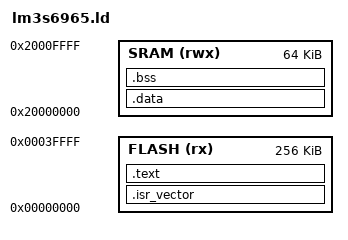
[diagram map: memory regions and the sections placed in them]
MEMORY
{
    FLASH (rx)  : ORIGIN = 0x00000000, LENGTH = 256K
    SRAM  (rwx) : ORIGIN = 0x20000000, LENGTH = 64K
}

ENTRY(Reset_Handler)

SECTIONS
{
    .isr_vector :
    {
        KEEP(*(.isr_vector))
    } > FLASH

    .text :
    {
        *(.text*)
        *(.rodata*)
        _sidata = .;
    } > FLASH

    .data : AT(_sidata)
    {
        _sdata = .;
        *(.data*)
        _edata = .;
    } > SRAM

    .bss :
    {
        _sbss = .;
        *(.bss*)
        *(COMMON)
        _ebss = .;
    } > SRAM

    _estack = ORIGIN(SRAM) + LENGTH(SRAM);

    /DISCARD/ :
    {
        *(.ARM.exidx*)
        *(.ARM.extab*)
    }
}
